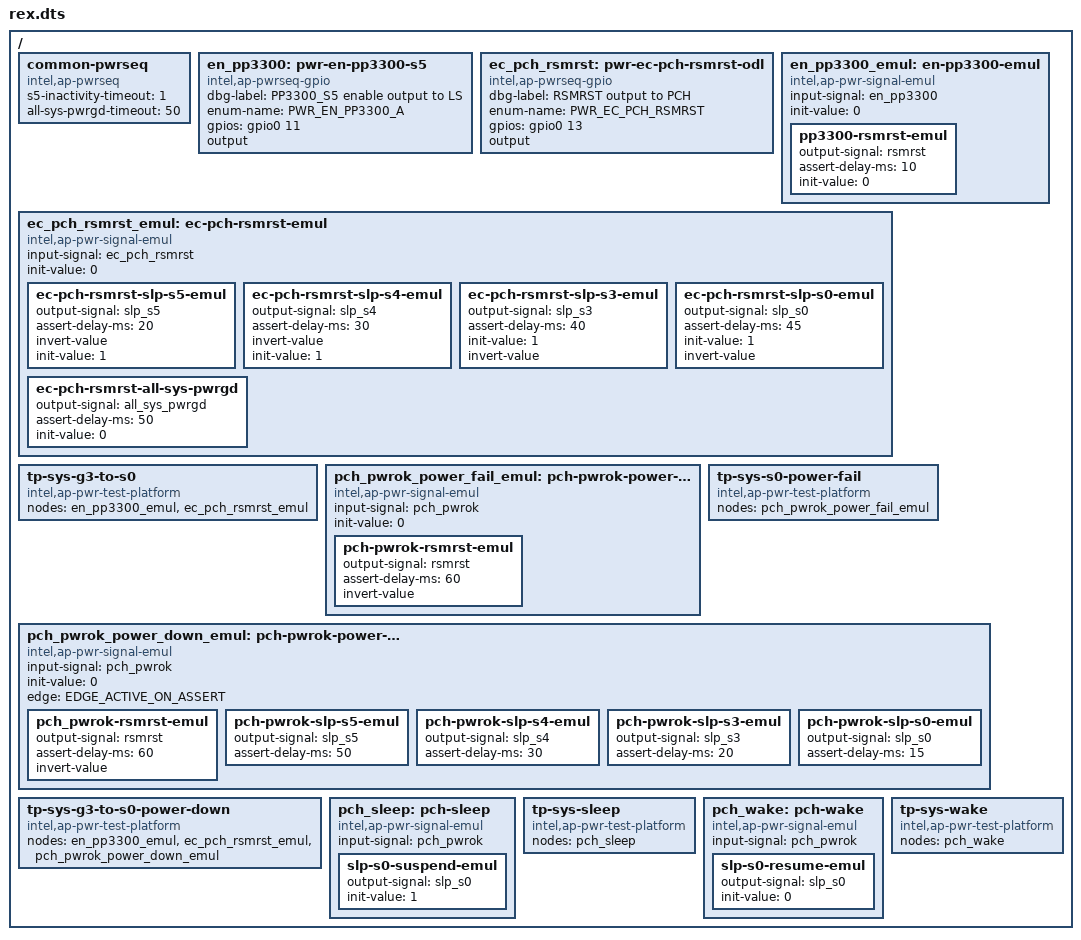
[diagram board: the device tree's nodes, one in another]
/* Copyright 2023 The ChromiumOS Authors
 * Use of this source code is governed by a BSD-style license that can be
 * found in the LICENSE file.
 */

#include <dt-bindings/gpio_defines.h>

/ {
	common-pwrseq {
		compatible = "intel,ap-pwrseq";
		s5-inactivity-timeout = <1>;
		all-sys-pwrgd-timeout = <50>;
	};

	en_pp3300: pwr-en-pp3300-s5 {
		compatible = "intel,ap-pwrseq-gpio";
		dbg-label = "PP3300_S5 enable output to LS";
		enum-name = "PWR_EN_PP3300_A";
		gpios = <&gpio0 11 0>;
		output;
	};
	ec_pch_rsmrst: pwr-ec-pch-rsmrst-odl {
		compatible = "intel,ap-pwrseq-gpio";
		dbg-label = "RSMRST output to PCH";
		enum-name = "PWR_EC_PCH_RSMRST";
		gpios = <&gpio0 13 0>;
		output;
	};
	en_pp3300_emul: en-pp3300-emul {
		compatible = "intel,ap-pwr-signal-emul";
		input-signal = <&en_pp3300>;
		init-value = <0>;
		pp3300-rsmrst-emul {
			output-signal = <&rsmrst>;
			assert-delay-ms = <10>;
			init-value= <0>;
		};
	};

	ec_pch_rsmrst_emul: ec-pch-rsmrst-emul {
		compatible = "intel,ap-pwr-signal-emul";
		input-signal = <&ec_pch_rsmrst>;
		init-value = <0>;
		ec-pch-rsmrst-slp-s5-emul {
			output-signal = <&slp_s5>;
			assert-delay-ms = <20>;
			invert-value;
			init-value= <1>;
		};
		ec-pch-rsmrst-slp-s4-emul {
			output-signal = <&slp_s4>;
			assert-delay-ms = <30>;
			invert-value;
			init-value= <1>;
		};
		ec-pch-rsmrst-slp-s3-emul {
			output-signal = <&slp_s3>;
			assert-delay-ms = <40>;
			init-value= <1>;
			invert-value;
		};
		ec-pch-rsmrst-slp-s0-emul {
			output-signal = <&slp_s0>;
			assert-delay-ms = <45>;
			init-value= <1>;
			invert-value;
		};
		ec-pch-rsmrst-all-sys-pwrgd {
			output-signal = <&all_sys_pwrgd>;
			assert-delay-ms = <50>;
			init-value= <0>;
		};
	};

	tp-sys-g3-to-s0 {
		compatible = "intel,ap-pwr-test-platform";
		nodes = <&en_pp3300_emul &ec_pch_rsmrst_emul>;
	};

	pch_pwrok_power_fail_emul: pch-pwrok-power-fail-emul {
		compatible = "intel,ap-pwr-signal-emul";
		input-signal = <&pch_pwrok>;
		init-value = <0>;
		pch-pwrok-rsmrst-emul {
			output-signal = <&rsmrst>;
			assert-delay-ms = <60>;
			invert-value;
		};
	};

	tp-sys-s0-power-fail {
		compatible = "intel,ap-pwr-test-platform";
		nodes = <&pch_pwrok_power_fail_emul>;
	};

	pch_pwrok_power_down_emul: pch-pwrok-power-down-emul {
		compatible = "intel,ap-pwr-signal-emul";
		input-signal = <&pch_pwrok>;
		init-value = <0>;
		edge = "EDGE_ACTIVE_ON_ASSERT";

		pch_pwrok-rsmrst-emul {
			output-signal = <&rsmrst>;
			assert-delay-ms = <60>;
			invert-value;
		};

		pch-pwrok-slp-s5-emul {
			output-signal = <&slp_s5>;
			assert-delay-ms = <50>;
		};

		pch-pwrok-slp-s4-emul {
			output-signal = <&slp_s4>;
			assert-delay-ms = <30>;
		};

		pch-pwrok-slp-s3-emul {
			output-signal = <&slp_s3>;
			assert-delay-ms = <20>;
		};

		pch-pwrok-slp-s0-emul {
			output-signal = <&slp_s0>;
			assert-delay-ms = <15>;
		};
	};

	tp-sys-g3-to-s0-power-down {
		compatible = "intel,ap-pwr-test-platform";
		nodes = <&en_pp3300_emul &ec_pch_rsmrst_emul
			      &pch_pwrok_power_down_emul>;
	};

	pch_sleep: pch-sleep {
		compatible = "intel,ap-pwr-signal-emul";
		input-signal = <&pch_pwrok>;

		slp-s0-suspend-emul {
			output-signal = <&slp_s0>;
			init-value=<1>;
		};
	};

	tp-sys-sleep {
		compatible = "intel,ap-pwr-test-platform";
		nodes = <&pch_sleep>;
	};

	pch_wake: pch-wake {
		compatible = "intel,ap-pwr-signal-emul";
		input-signal = <&pch_pwrok>;

		slp-s0-resume-emul {
			output-signal = <&slp_s0>;
			init-value=<0>;
		};
	};

	tp-sys-wake {
		compatible = "intel,ap-pwr-test-platform";
		nodes = <&pch_wake>;
	};

};
